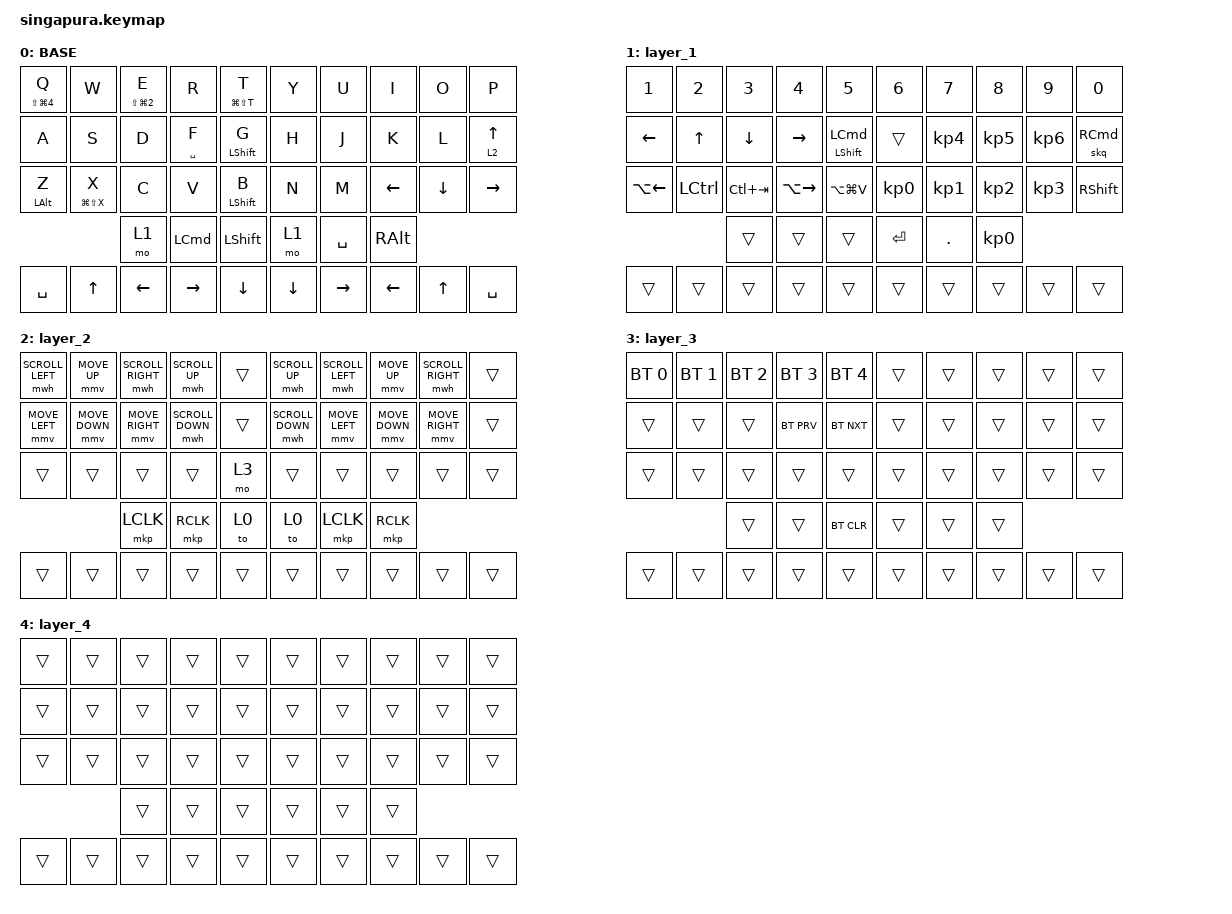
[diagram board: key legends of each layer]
// Copyright 2023 saikocat (@saikocat)
// SPDX-License-Identifier: MIT

#include <behaviors.dtsi>
#include <dt-bindings/zmk/bt.h>
#include <dt-bindings/zmk/keys.h>
#include <dt-bindings/zmk/mouse.h>

#define U_MOUSE_MOVE_MAX 1400

#undef MOVE_UP
#undef MOVE_DOWN
#undef MOVE_LEFT
#undef MOVE_RIGHT

#define MOVE_UP MOVE_VERT(-U_MOUSE_MOVE_MAX)
#define MOVE_DOWN MOVE_VERT(U_MOUSE_MOVE_MAX)
#define MOVE_LEFT MOVE_HOR(-U_MOUSE_MOVE_MAX)
#define MOVE_RIGHT MOVE_HOR(U_MOUSE_MOVE_MAX)
#define U_MOUSE_SCROLL_MAX 12

#undef SCROLL_UP
#undef SCROLL_DOWN
#undef SCROLL_LEFT
#undef SCROLL_RIGHT

#define SCROLL_UP SCROLL_VERT(U_MOUSE_SCROLL_MAX)
#define SCROLL_DOWN SCROLL_VERT(-U_MOUSE_SCROLL_MAX)
#define SCROLL_LEFT SCROLL_HOR(-U_MOUSE_SCROLL_MAX)
#define SCROLL_RIGHT SCROLL_HOR(U_MOUSE_SCROLL_MAX)

&mmv {
    time-to-max-speed-ms = <250>;
    acceleration-exponent = <1>;
};

&mwh {
    time-to-max-speed-ms = <250>;
    acceleration-exponent = <1>;
};

&nice_view_spi { cs-gpios = <&pro_micro 10 GPIO_ACTIVE_HIGH>; };

&caps_word { continue-list = <UNDERSCORE MINUS BSPC RSHFT LSHFT>; };

&lt {
    flavor = "balanced";
    tapping-term-ms = <750>;
    quick-tap-ms = <500>;
};

/ {
    behaviors {
        skq: sticky_key_quick_release {
            label = "STICKY_KEY_QUICK_RELEASE";
            compatible = "zmk,behavior-sticky-key";
            #binding-cells = <1>;
            bindings = <&kp>;
            release-after-ms = <2000>;
            quick-release;
            ignore-modifiers;
        };

        gqt: global-quick-tap {
            compatible = "zmk,behavior-hold-tap";
            label = "GLOBAL_QUICK_TAP";
            #binding-cells = <2>;
            flavor = "tap-preferred";
            tapping-term-ms = <250>;
            quick-tap-ms = <150>;
            global-quick-tap;
            bindings = <&kp>, <&kp>;
        };
    };
};

/ {
    combos {
        compatible = "zmk,combos";

        combo_esc {
            timeout-ms = <50>;
            key-positions = <0 1>;
            bindings = <&kp ESC>;
        };

        combo_tab {
            bindings = <&kp TAB>;
            key-positions = <13 12>;
        };

        combo_exclaimation {
            bindings = <&kp EXCLAMATION>;
            key-positions = <2 1>;
        };

        combo_hash {
            bindings = <&kp HASH>;
            key-positions = <0 2>;
        };

        combo_dollar {
            bindings = <&kp DOLLAR>;
            key-positions = <0 4>;
        };

        combo_percent {
            bindings = <&kp PERCENT>;
            key-positions = <1 3>;
        };

        combo_ampersand {
            bindings = <&kp AMPERSAND>;
            key-positions = <17 16>;
        };

        combo_caret {
            bindings = <&kp CARET>;
            key-positions = <18 16>;
        };

        combo_asterisk {
            bindings = <&kp ASTERISK>;
            key-positions = <18 17>;
        };

        combo_left_parenthesis {
            bindings = <&kp LEFT_PARENTHESIS>;
            key-positions = <6 7>;
        };

        combo_right_parenthesis {
            bindings = <&kp RIGHT_PARENTHESIS>;
            key-positions = <7 8>;
        };

        combo_backspace {
            bindings = <&kp BACKSPACE>;
            key-positions = <6 5>;
        };

        combo_delete {
            bindings = <&kp DELETE>;
            key-positions = <4 3>;
        };

        combo_underscore {
            bindings = <&kp UNDERSCORE>;
            key-positions = <23 24>;
        };

        combo_minus {
            bindings = <&kp MINUS>;
            key-positions = <14 13>;
        };

        combo_plus {
            bindings = <&kp PLUS>;
            key-positions = <25 26>;
        };

        combo_equal {
            bindings = <&kp EQUAL>;
            key-positions = <15 16>;
        };

        combo_single_quote {
            bindings = <&kp SINGLE_QUOTE>;
            key-positions = <9 8>;
        };

        combo_double_quote {
            bindings = <&kp APOSTROPHE>;
            key-positions = <9 18 17>;
        };

        combo_question {
            bindings = <&kp QUESTION>;
            key-positions = <17 16 18>;
        };

        combo_comma {
            bindings = <&kp COMMA>;
            key-positions = <15 6 7>;
        };

        combo_dot {
            bindings = <&kp DOT>;
            key-positions = <8 7 16>;
        };

        combo_left_bracket {
            bindings = <&kp LEFT_BRACKET>;
            key-positions = <28 27>;
        };

        combo_right_bracket {
            bindings = <&kp RIGHT_BRACKET>;
            key-positions = <29 28>;
        };

        combo_backslash {
            bindings = <&kp BACKSLASH>;
            key-positions = <19 18>;
        };

        combo_left_option {
            bindings = <&kp LEFT_ALT>;
            key-positions = <20 32>;
        };

        combo_left_control {
            bindings = <&kp LEFT_CONTROL>;
            key-positions = <30 20>;
        };

        combo_Downloads_folder {
            bindings = <&kp LA(Z)>;
            key-positions = <20 21 32>;
        };

        combo_enter_left {
            bindings = <&kp ENTER>;
            key-positions = <1 2 3>;
        };

        combo_enter_right {
            bindings = <&kp ENTER>;
            key-positions = <8 7 6>;
        };

        combo_space_1 {
            bindings = <&kp SPACE>;
            key-positions = <0 1 2>;
        };

        combo_media_next {
            bindings = <&kp C_FF>;
            key-positions = <22 13>;
        };

        combo_media_previous {
            bindings = <&kp C_REWIND>;
            key-positions = <21 10>;
        };

        combo_volume_up {
            bindings = <&kp C_VOLUME_UP>;
            key-positions = <22 23>;
        };

        combo_volume_down {
            bindings = <&kp C_VOLUME_DOWN>;
            key-positions = <20 21>;
        };

        combo_mute {
            bindings = <&kp C_MUTE>;
            key-positions = <22 21 20>;
        };

        combo_colon {
            bindings = <&kp COLON>;
            key-positions = <26 27 28>;
        };

        combo_semicolon {
            bindings = <&kp SEMICOLON>;
            key-positions = <25 26 27>;
        };

        combo_reopen_tab {
            bindings = <&kp LS(LG(T))>;
            key-positions = <20 31 4>;
        };

        combo_at_sign {
            bindings = <&kp AT_SIGN>;
            key-positions = <11 12 13>;
        };

        combo_space_2 {
            bindings = <&kp SPACE>;
            key-positions = <14 13 12>;
        };

        combo_media_play {
            bindings = <&kp C_PLAY_PAUSE>;
            key-positions = <21 22>;
        };

        combo_up {
            bindings = <&kp UP_ARROW>;
            key-positions = <18 27>;
        };

        new_combo {
            bindings = <&kp UP_ARROW>;
            key-positions = <18 29>;
        };

        combo_slash {
            bindings = <&kp SLASH>;
            key-positions = <9 8 17>;
        };

        combo_right_window {
            bindings = <&kp RC(RIGHT)>;
            key-positions = <29 35>;
        };

        combo_left_window {
            bindings = <&kp RC(LEFT)>;
            key-positions = <35 27>;
        };

        combo_sweat_emote {
            bindings = <&macro_sweat>;
            key-positions = <20 13>;
        };

        combo_thumbs_up_emote {
            bindings = <&macro_thumbs_up>;
            key-positions = <20 14>;
        };

        combo_cheers_benroy {
            bindings = <&marco_cheers_benroy>;
            key-positions = <31 20 14>;
        };

        combo_meme {
            bindings = <&macro_meme>;
            key-positions = <29 25>;
        };

        combo_mouse {
            bindings = <&to 2>;
            key-positions = <19 15>;
        };

        combo_mouse_left {
            bindings = <&to 2>;
            key-positions = <20 24>;
        };

        combo_joy_emote {
            bindings = <&macro_joy_emote>;
            key-positions = <20 12>;
        };

        combo_pathetic_meme {
            bindings = <&marco_pathetic>;
            key-positions = <25 27 28>;
        };

        combo_right_shift {
            bindings = <&skq RIGHT_SHIFT>;
            key-positions = <26 27>;
        };

        combo_right_command {
            bindings = <&kp RIGHT_COMMAND>;
            key-positions = <35 9>;
        };

        combo_right_shift_2 {
            bindings = <&kp RIGHT_SHIFT>;
            key-positions = <19 35>;
        };

        combo_desktop_left {
            bindings = <&kp LC(LEFT_ARROW)>;
            key-positions = <3 13>;
        };

        combo_desktop_right {
            bindings = <&kp LC(RIGHT)>;
            key-positions = <14 4>;
        };
    };

    macros {
        macro_meme: macro_meme {
            compatible = "zmk,behavior-macro";
            label = "MACRO_MEME";
            #binding-cells = <0>;
            bindings = <&none &kp LS(I) &kp SPACE &kp F &kp E &kp E &kp L &kp SPACE &kp L &kp I &kp K &kp E &kp SPACE &kp W &kp E &kp SPACE &kp H &kp A &kp V &kp E &kp SPACE &kp G &kp O &kp N &kp E &kp SPACE &kp P &kp A &kp S &kp T &kp SPACE &kp S &kp O &kp C &kp I &kp A &kp L &kp SPACE &kp N &kp O &kp R &kp M &kp S &kp SPACE &kp H &kp A &kp H &kp H &kp A &kp A &kp H &kp A &kp H &kp H &kp H &kp ENTER>;
        };

        macro_thumbs_up: macro_thumbs_up {
            compatible = "zmk,behavior-macro";
            label = "MACRO_THUMBS_UP";
            #binding-cells = <0>;
            bindings = <&none &kp COLON &kp T &kp H &kp U &kp M &kp B &kp ENTER>;
        };

        macro_sweat: macro_sweat {
            compatible = "zmk,behavior-macro";
            label = "MACRO_SWEAT";
            #binding-cells = <0>;
            bindings = <&none &kp COLON &kp S &kp W &kp E &kp A &kp T>;
        };

        marco_cheers_benroy: marco_cheers_benroy {
            compatible = "zmk,behavior-macro";
            label = "MARCO_CHEERS_BENROY";
            #binding-cells = <0>;
            bindings = <&none &kp LS(C) &kp H &kp E &kp E &kp R &kp S &kp EXCL &kp RET &kp LS(B) &kp E &kp N &kp R &kp O &kp Y>;
        };

        macro_joy_emote: macro_joy_emote {
            compatible = "zmk,behavior-macro";
            label = "MACRO_JOY_EMOTE";
            #binding-cells = <0>;
            bindings = <&none &kp COLON &kp J &kp O &kp Y &kp COLON>;
        };

        marco_pathetic: marco_pathetic {
            compatible = "zmk,behavior-macro";
            label = "MARCO_PATHETIC";
            #binding-cells = <0>;
            bindings = <&none &kp LS(N) &kp O &kp T &kp SPACE &kp B &kp E &kp C &kp A &kp U &kp S &kp E &kp SPACE &kp LS(I) &kp SPACE &kp A &kp M &kp SPACE &kp P &kp A &kp T &kp R &kp I &kp O &kp T &kp I &kp C &kp SPACE &kp B &kp U &kp T &kp SPACE &kp B &kp E &kp C &kp A &kp U &kp S &kp E &kp SPACE &kp LS(I) &kp SPACE &kp A &kp M &kp SPACE &kp P &kp A &kp T &kp H &kp E &kp T &kp I &kp C>;
        };
    };

    keymap {
        compatible = "zmk,keymap";

        layer_base {
            label = "BASE";
            bindings = <
&gqt LS(LG(NUMBER_4)) Q  &kp W             &gqt LS(LG(NUMBER_2)) E  &kp R             &gqt LG(LS(T)) T     &kp Y     &kp U      &kp I     &kp O     &kp P
&kp A                    &kp S             &kp D                    &gqt SPACE F      &gqt LEFT_SHIFT G    &kp H     &kp J      &kp K     &kp L     &lt 2 UP_ARROW
&gqt LEFT_ALT Z          &gqt LG(LS(X)) X  &kp C                    &kp V             &gqt LEFT_SHIFT B    &kp N     &kp M      &kp LEFT  &kp DOWN  &kp RIGHT
                                           &mo 1                    &kp LEFT_COMMAND  &kp LEFT_SHIFT       &mo 1     &kp SPACE  &kp RALT
&kp SPACE                &kp UP            &kp LEFT                 &kp RIGHT         &kp DOWN             &kp DOWN  &kp RIGHT  &kp LEFT  &kp UP    &kp SPACE
            >;
        };

        layer_1 {
            bindings = <
&kp NUMBER_1    &kp NUMBER_2      &kp NUMBER_3    &kp N4         &kp NUMBER_5                    &kp NUMBER_6     &kp NUMBER_7     &kp N8           &kp NUMBER_9     &kp N0
&kp LEFT_ARROW  &kp UP_ARROW      &kp DOWN_ARROW  &kp RIGHT      &gqt LEFT_SHIFT LEFT_COMMAND    &trans           &kp KP_NUMBER_4  &kp KP_NUMBER_5  &kp KP_NUMBER_6  &skq RIGHT_COMMAND
&kp LA(LEFT)    &kp LEFT_CONTROL  &kp LC(TAB)     &kp LA(RIGHT)  &kp LA(LG(V))                   &kp KP_NUMBER_0  &kp KP_NUMBER_1  &kp KP_NUMBER_2  &kp KP_NUMBER_3  &kp RIGHT_SHIFT
                                  &trans          &trans         &trans                          &kp ENTER        &kp PERIOD       &kp KP_N0
&trans          &trans            &trans          &trans         &trans                          &trans           &trans           &trans           &trans           &trans
            >;
        };

        layer_2 {
            bindings = <
&mwh SCROLL_LEFT  &mmv MOVE_UP    &mwh SCROLL_RIGHT  &mwh SCROLL_UP    &trans    &mwh SCROLL_UP    &mwh SCROLL_LEFT  &mmv MOVE_UP    &mwh SCROLL_RIGHT  &trans
&mmv MOVE_LEFT    &mmv MOVE_DOWN  &mmv MOVE_RIGHT    &mwh SCROLL_DOWN  &trans    &mwh SCROLL_DOWN  &mmv MOVE_LEFT    &mmv MOVE_DOWN  &mmv MOVE_RIGHT    &trans
&trans            &trans          &trans             &trans            &mo 3     &trans            &trans            &trans          &trans             &trans
                                  &mkp LCLK          &mkp RCLK         &to 0     &to 0             &mkp LCLK         &mkp RCLK
&trans            &trans          &trans             &trans            &trans    &trans            &trans            &trans          &trans             &trans
            >;
        };

        layer_3 {
            bindings = <
&bt BT_SEL 0  &bt BT_SEL 1  &bt BT_SEL 2  &bt BT_SEL 3  &bt BT_SEL 4    &trans  &trans  &trans  &trans  &trans
&trans        &trans        &trans        &bt BT_PRV    &bt BT_NXT      &trans  &trans  &trans  &trans  &trans
&trans        &trans        &trans        &trans        &trans          &trans  &trans  &trans  &trans  &trans
                            &trans        &trans        &bt BT_CLR      &trans  &trans  &trans
&trans        &trans        &trans        &trans        &trans          &trans  &trans  &trans  &trans  &trans
            >;
        };

        layer_4 {
            bindings = <
&trans  &trans  &trans  &trans  &trans    &trans  &trans  &trans  &trans  &trans
&trans  &trans  &trans  &trans  &trans    &trans  &trans  &trans  &trans  &trans
&trans  &trans  &trans  &trans  &trans    &trans  &trans  &trans  &trans  &trans
                &trans  &trans  &trans    &trans  &trans  &trans
&trans  &trans  &trans  &trans  &trans    &trans  &trans  &trans  &trans  &trans
            >;
        };
    };
};

// vim: ft=dts et
